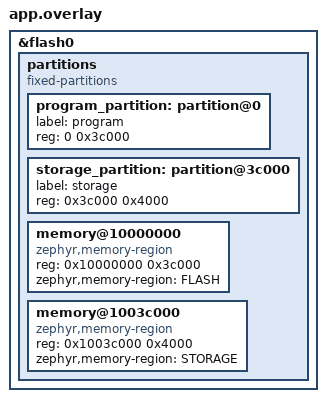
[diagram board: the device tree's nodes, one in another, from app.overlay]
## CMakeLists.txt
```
# Copyright (c) 2025 Analog Devices, Inc.
# SPDX-License-Identifier: Apache-2.0

cmake_minimum_required(VERSION 3.20.0)

find_package(Zephyr REQUIRED HINTS $ENV{ZEPHYR_BASE})

# Build app
project(motor_control)

target_sources(app PRIVATE
	src/main.c
	objdict/OD.c
	src/cia402.c
	src/tmc9660_params.c
)

zephyr_include_directories(objdict)
```

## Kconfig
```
# Copyright (c) 2025 Analog Devices, Inc.
# SPDX-License-Identifier: Apache-2.0

menu "Zephyr"
source "Kconfig.zephyr"
endmenu

menu "ADRD motor drive"

config SHELL_TMC_PARAMS
    bool "tmc_params shell command"
    depends on SHELL

config TMC_PARAMS_REFSW
    bool "Use parameters relating to reference switch"
    default n

config TMC_PARAMS_ABN1
    bool "Use parameters relating to ABN1 encoder"
    default y
    
config TMC_PARAMS_ABN2
    bool "Use parameters relating to ABN2 encoder"
    default n

config TMC_PARAMS_SPI
    bool "Use parameters relating to SPI encoder"
    default n
    
config TMC_PARAMS_HALL
    bool "Use parameters relating to Hall encoder"
    default y

config TMC_PARAMS_STEPDIR
    # ioan: would we *ever* need this on this board?
    bool "Use parameters relating to STEP/DIR input"
    default n

config TMC_RWE_PARAM_NAMES
    bool "Provide name strings for TMC9660 RWE parameters"
    depends on SHELL_TMC_PARAMS

config CIA402_THREAD_STACK_SIZE
    int "CiA 402 thread stack size"
    default 1024

endmenu
```

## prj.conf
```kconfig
# Copyright (c) 2024-2025 Analog Devices, Inc.
# SPDX-License-Identifier: Apache-2.0

CONFIG_CAN=y
CONFIG_CANOPEN=y
CONFIG_CANOPEN_LOG_LEVEL_INF=y
CONFIG_CANOPENNODE=y
CONFIG_CANOPENNODE_CONFIG_FILE="CO_config_custom.h"
CONFIG_CANOPENNODE_MAINLINE_THREAD_STACK_SIZE=1024
CONFIG_CANOPENNODE_SYNC_THREAD_STACK_SIZE=1024

CONFIG_CANOPENNODE_LEDS_USE_GPIO=n
CONFIG_CANOPENNODE_LEDS_USE_CALLBACK=y

CONFIG_LOG=y
CONFIG_REBOOT=y
CONFIG_LOG_SPEED=y

# CONFIG_CAN_LOG_LEVEL_DBG=y
# CONFIG_CANOPEN_LOG_LEVEL_DBG=y
CONFIG_CANOPEN_LOG_LEVEL_INF=y

CONFIG_SHELL=y
CONFIG_SHELL_MINIMAL=n
CONFIG_SHELL_TMC_PARAMS=y
CONFIG_TMC_RWE_PARAM_NAMES=n

CONFIG_FLASH=y
CONFIG_FLASH_MAP=y
CONFIG_SETTINGS=y
CONFIG_SETTINGS_RUNTIME=y
CONFIG_ZMS=y
CONFIG_SETTINGS_ZMS=y

CONFIG_COMMON_LIBC_MALLOC=y
CONFIG_BUILD_OUTPUT_META=y
```

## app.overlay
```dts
/*
 * Copyright (c) 2024-2025 Analog Devices, Inc.
 *
 * SPDX-License-Identifier: Apache-2.0
 */

&flash0 {
    partitions {
        compatible = "fixed-partitions";
        #address-cells = <0x1>;
        #size-cells = <0x1>;

        program_partition: partition@0 {
            label = "program";
            reg = <0 0x3c000>;
        };

        storage_partition: partition@3c000 {
            label = "storage";
            reg = <0x3c000 0x4000>;
        };

        /* Inform linker: */
        memory@10000000 {
            compatible = "zephyr,memory-region";
            reg = <0x10000000 0x3c000>;
            zephyr,memory-region = "FLASH";
        };

        memory@1003c000 {
            compatible = "zephyr,memory-region";
            reg = <0x1003c000 0x4000>;
            zephyr,memory-region = "STORAGE";
        };
    };
};
```

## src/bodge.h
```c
/*
 * Copyright (c) 2025 Analog Devices, Inc.
 *
 * SPDX-License-Identifier: Apache-2.0
 */

#ifndef BODGE_H_
#define BODGE_H_

#include <wrap_max32_sys.h>

static inline void calibrate_oscillator()
{
	MXC_SYS_ClockCalibrate(MXC_SYS_CLOCK_IPO);
}

#endif /* BODGE_H_ */
```

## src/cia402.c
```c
/*
 * Copyright (c) 2025 Analog Devices, Inc.
 *
 * SPDX-License-Identifier: Apache-2.0
 */

#include <zephyr/logging/log.h>
#include <stdlib.h>

#include "cia402.h"
#include "cia402_impl.h"

LOG_MODULE_REGISTER(cia402, LOG_LEVEL_INF);

enum cia402_statusword_bit {
    CIA402_SW_READYTOSWITCHON = 1 << 0,  // Ready to switch on
    CIA402_SW_SWITCHON = 1 << 1,         // Switched on (voltage applied to drive)
    CIA402_SW_OPERATIONEN = 1 << 2,      // Operation Enabled (+ quick stop / fault reaction)
    CIA402_SW_FAULT = 1 << 3,
    CIA402_SW_VOLTAGEEN = 1 << 4,        // Voltage is applied to drive
    CIA402_SW_QUICKSTOP = 1 << 5,        // 
    CIA402_SW_SWITCHONDISABLED = 1 << 6, //
    CIA402_SW_WARNING = 1 << 7,          // 
    CIA402_SW_MANUF1 = 1 << 8,           // Manufacturer-specific, unused
    CIA402_SW_REMOTE = 1 << 9,           // Set to 0 if PDOs are ignored (never??)
    CIA402_SW_TARGET = 1 << 10,          // Target reached
    CIA402_SW_LIMIT = 1 << 11,           // Internal limit active (e.g. software position limit)
    CIA402_SW_MOP1 = 1 << 12,            // Mode-of-operation specific:
    CIA402_SW_PP_ACK = CIA402_SW_MOP1,   // pp: Set-point acknowledge
    CIA402_SW_PV_SPEED = CIA402_SW_MOP1, // pv: Speed
    CIA402_SW_CS_FOL = CIA402_SW_MOP1,   // csp, csv, cst: Drive follows the command value
    CIA402_SW_MOP2 = 1 << 13,            // Mode-of-operation specific:
    CIA402_SW_PP_ERR = CIA402_SW_MOP2,   // pp: Following error
    CIA402_SW_PV_ERR = CIA402_SW_MOP2,   // pv: Max slippage error
    CIA402_SW_CS_ERR = CIA402_SW_MOP2,   // csp, csv, cst: Folowing error
    CIA402_SW_MANUF2 = 1 << 14,          // Manufacturer-specific, unused
    CIA402_SW_MANUF3 = 1 << 15,          // Manufacturer-specific, unused
};

enum cia402_controlword_bit {
    CIA402_CW_SWITCH_ON = 1 << 0,        // Switch on
    CIA402_CW_ENABLE_VOLTAGE = 1 << 1,   // Enable voltage
    CIA402_CW_QUICK_STOP = 1 << 2,       // Quick stop (0 = quick stop)
    CIA402_CW_ENABLE_OPERATION = 1 << 3, // Enable operation
    CIA402_CW_MOP1 = 1 << 4,             // Mode-of-operation specific:
    CIA402_CW_PP_NEWSP = CIA402_CW_MOP1, // pp: New set-point
    CIA402_CW_MOP2 = 1 << 5,             // Mode-of-operation specific:
    CIA402_CW_PP_IMM = CIA402_CW_MOP2,   // pp: Immediately assume set-point
    CIA402_CW_MOP3 = 1 << 6,             // Mode-of-operation specific:
    CIA402_CW_PP_REL = CIA402_CW_MOP3,   // pp: Set-point is relative
    CIA402_CW_FAULT_RESET = 1 << 7,      // Fault reset
    CIA402_CW_HALT = 1 << 8,             // Halt
};

struct cia402_priv {
    struct k_mutex lock; // ioan: What did I intend to symchronize with this lock...?

    // Profile position state
    bool pp_target_reached;
    int pp_target;
};

// CIA402_STATE_NOT_READY_TO_SWITCH_ON: low power, disabled drive, brake enabled if exists. run self-test + init
static inline void enter_not_ready_to_switch_on(struct cia402 *cia402) {
    LOG_INF("Entering state: NOT_READY_TO_SWITCH_ON");

    *cia402->statusword = 0;
    cia402_impl_statusword_tpdo(cia402);
}


// CIA402_STATE_SWITCH_ON_DISABLED: self-test + init ok. idle powered-down state
static inline void enter_switch_on_disabled(struct cia402 *cia402) {
    LOG_INF("Entering state: SWITCH_ON_DISABLED");

    cia402_impl_shutdown(cia402);

    int sw = *cia402->statusword;
    sw = (sw & ~0b1001111) | 0b1000000; // x1xx 0000
    sw &= ~CIA402_SW_VOLTAGEEN;
    // sw |= CIA402_SW_REMOTE; // ioan: is this the right place?
    *cia402->statusword = sw;
    cia402_impl_statusword_tpdo(cia402);
}


// CIA402_STATE_READY_TO_SWITCH_ON: maybe high power, drive disabled. intermediary state during motor power-up
static inline void enter_ready_to_switch_on(struct cia402 *cia402) {
    LOG_INF("Entering state: READY_TO_SWITCH_ON");
    
    int sw = *cia402->statusword;
    sw = (sw & ~0b1101111) | 0b0100001; // x01x 0001
    sw &= ~CIA402_SW_VOLTAGEEN;
    *cia402->statusword = sw;
    cia402_impl_statusword_tpdo(cia402);
}


// CIA402_STATE_SWITCHED_ON: high power, drive disabled. intermediary state during motor power-up
static inline void enter_switched_on(struct cia402 *cia402) {
    LOG_INF("Entering state: SWITCHED_ON");

    cia402_impl_start(cia402);
    
    int sw = *cia402->statusword;
    sw = (sw & ~0b1101111) | 0b0100011; // x01x 0011
    sw |= CIA402_SW_VOLTAGEEN;
    *cia402->statusword = sw;
    cia402_impl_statusword_tpdo(cia402);
}


// CIA402_STATE_OPERATION_ENABLED: high power, drive enabled, motor actively communicating and moving
static inline void enter_operation_enabled(struct cia402 *cia402) {
    LOG_INF("Entering state: OPERATION_ENABLED");
    
    int sw = *cia402->statusword;
    sw = (sw & ~0b1101111) | 0b0100111; // x01x 0111
    sw |= CIA402_SW_VOLTAGEEN;
    *cia402->statusword = sw;
    cia402_impl_statusword_tpdo(cia402);
}

static inline void run_mode_pp(struct cia402 *cia402) {
    uint16_t controlword = *cia402->controlword;
    uint16_t statusword = *cia402->statusword;

    // Parse controlword
    if(controlword & CIA402_CW_PP_NEWSP) {
        if((controlword & CIA402_CW_PP_IMM) || (cia402->priv->pp_target_reached || true)) { // target_reached doesn't work yet
            if(controlword & CIA402_CW_PP_REL) {
                // TODO: object 60F2 - relative to what
                cia402->priv->pp_target += *cia402->target_pos;
            } else {
                cia402->priv->pp_target = *cia402->target_pos;
            }

            statusword |= CIA402_SW_PP_ACK;
            *cia402->statusword = statusword;
            cia402_impl_statusword_tpdo(cia402);
        }
    } else {
        // Un-assert "ack" only after master un-asserts "new set-point"
        if(statusword & CIA402_SW_PP_ACK) {
            statusword &= ~CIA402_SW_PP_ACK;
            *cia402->statusword = statusword;
            cia402_impl_statusword_tpdo(cia402);
        }
    }

    bool halt = controlword & CIA402_CW_HALT;

    // Execute
    struct cia402_impl_pp_out out = cia402_impl_pp((struct cia402_impl_pp_in) {
        .halt = halt,
        .target_pos = cia402->priv->pp_target
    });

    // Set statusword
    statusword &= ~(CIA402_SW_PP_ERR | CIA402_SW_TARGET);
    if(out.pp_err) statusword |= CIA402_SW_PP_ERR;
    if(out.target_reached) statusword |= CIA402_SW_TARGET;
    *cia402->statusword = statusword;
}

static inline void run_mode_pv(struct cia402 *cia402) {
    uint16_t controlword = *cia402->controlword;
    uint16_t statusword = *cia402->statusword;

    // Parse controlword
    bool halt = controlword & CIA402_CW_HALT;

    // Execute
    struct cia402_impl_pv_out out = cia402_impl_pv((struct cia402_impl_pv_in) {
        .halt = halt,
        .target_vel = *cia402->target_vel
    });

    // Set statusword
    statusword &= ~(CIA402_SW_PV_SPEED | CIA402_SW_PV_ERR | CIA402_SW_TARGET);
    if(out.speed) statusword |= CIA402_SW_PV_SPEED;
    if(out.max_slip_err) statusword |= CIA402_SW_PV_ERR;    
    if(out.target_reached) statusword |= CIA402_SW_TARGET;
    *cia402->statusword = statusword;
}

static inline void run_mode_tq(struct cia402 *cia402) {
    uint16_t controlword = *cia402->controlword;
    uint16_t statusword = *cia402->statusword;

    // Parse controlword
    bool halt = controlword & CIA402_CW_HALT;

    // TODO: implement torque slope (object 6087)

    struct cia402_impl_tq_out out = cia402_impl_tq((struct cia402_impl_tq_in) {
        .halt = halt,
        .target_tor = *cia402->target_tor
    });

    statusword &= ~CIA402_SW_TARGET;
    if(out.target_reached) statusword |= CIA402_SW_TARGET;
    *cia402->statusword = statusword;
}

static inline void run_mode_csp(struct cia402 *cia402) {
    uint16_t statusword = *cia402->statusword;

    // Controlword: Cyclic synchronous modes have no mode-specific bits

    // Execute
    struct cia402_impl_csp_out out = cia402_impl_csp((struct cia402_impl_csp_in) {
        .target_pos = *cia402->target_pos
    });

    // Set statusword
    statusword &= ~(CIA402_SW_CS_ERR | CIA402_SW_CS_FOL);
    if(out.following_err) statusword |= CIA402_SW_CS_ERR;
    if(out.following) statusword |= CIA402_SW_CS_FOL;
    *cia402->statusword = statusword;
}

static inline void run_mode_csv(struct cia402 *cia402) {
    uint16_t statusword = *cia402->statusword;

    // Controlword: Cyclic synchronous modes have no mode-specific bits

    // Execute
    struct cia402_impl_csv_out out = cia402_impl_csv((struct cia402_impl_csv_in) {
        .target_vel = *cia402->target_vel
    });

    // Set statusword
    statusword &= ~(CIA402_SW_CS_ERR | CIA402_SW_CS_FOL);
    if(out.following) statusword |= CIA402_SW_CS_FOL;
    *cia402->statusword = statusword;
}

static inline void run_mode_cst(struct cia402 *cia402) {
    uint16_t statusword = *cia402->statusword;

    // Controlword: Cyclic synchronous modes have no mode-specific bits

    // Execute
    struct cia402_impl_cst_out out = cia402_impl_cst((struct cia402_impl_cst_in) {
        .target_tor = *cia402->target_tor
    });

    // Set statusword
    statusword &= ~(CIA402_SW_CS_ERR | CIA402_SW_CS_FOL);
    if(out.following) statusword |= CIA402_SW_CS_FOL;
    *cia402->statusword = statusword;
}

static inline void run_operation_enabled(struct cia402 *cia402) {
    const uint16_t initial_statusword = *cia402->statusword;
    enum cia402_mode_of_operation mode_req = *cia402->mop;
    enum cia402_mode_of_operation mode = *cia402->mop_display;

    // Handle mode change
    if(mode_req != mode) {
        LOG_INF("Setting mode of operation: %d %s", mode_req,
            mode_req == CIA402_MODE_PROFILE_POSITION ? "pp" :
            mode_req == CIA402_MODE_PROFILE_VELOCITY ? "pv" :
            mode_req == CIA402_MODE_PROFILE_TORQUE ? "tq" :
            mode_req == CIA402_MODE_CYCLIC_SYNCHRONOUS_POSITION ? "csp" :
            mode_req == CIA402_MODE_CYCLIC_SYNCHRONOUS_VELOCITY ? "csv" :
            mode_req == CIA402_MODE_CYCLIC_SYNCHRONOUS_TORQUE ? "cst" : "??");

        // Reset mode-specific bits
        cia402->priv->pp_target = *cia402->current_pos;
        cia402->priv->pp_target_reached = false;

        *cia402->mop_display = mode = mode_req;
        cia402_impl_mop_tpdo(cia402);
        cia402_impl_statusword_tpdo(cia402);
    }

    // Mode-specific logic
    switch(mode) {
        default: cia402_impl_halt(cia402); break; // Invalid mode
        case CIA402_MODE_PROFILE_POSITION:            run_mode_pp(cia402);  break;
        case CIA402_MODE_PROFILE_VELOCITY:            run_mode_pv(cia402);  break;
        case CIA402_MODE_PROFILE_TORQUE:              run_mode_tq(cia402);  break;
        case CIA402_MODE_CYCLIC_SYNCHRONOUS_POSITION: run_mode_csp(cia402); break;
        case CIA402_MODE_CYCLIC_SYNCHRONOUS_VELOCITY: run_mode_csv(cia402); break;
        case CIA402_MODE_CYCLIC_SYNCHRONOUS_TORQUE:   run_mode_cst(cia402); break;
    }

    if(*cia402->statusword != initial_statusword) {
        cia402_impl_statusword_tpdo(cia402);
    }
}


// CIA402_STATE_QUICK_STOP_ACTIVE: stop motor, then go to SWITCH_ON_DISABLED
static inline void enter_quick_stop_active(struct cia402 *cia402) {
    LOG_INF("Entering state: QUICK_STOP_ACTIVE");

    cia402_impl_stop(cia402);
    
    int sw = *cia402->statusword;
    sw = (sw & ~0b1101111) | 0b0000111; // x00x 0111
    *cia402->statusword = sw;
    cia402_impl_statusword_tpdo(cia402);
}


// CIA402_STATE_FAULT_REACTION_ACTIVE: stop motor, then go to FAULT
static inline void enter_fault_reaction_active(struct cia402 *cia402) {
    LOG_INF("Entering state: FAULT_REACTION_ACTIVE");

    cia402_impl_stop(cia402);
    
    int sw = *cia402->statusword;
    sw = (sw & ~0b1001111) | 0b0001111; // x0xx 1111
    *cia402->statusword = sw;
    cia402_impl_statusword_tpdo(cia402);
}

// CIA402_STATE_FAULT: stay in this state until explicitly taken out
static inline void enter_fault(struct cia402 *cia402) {
    LOG_INF("Entering state: FAULT");
    
    cia402_impl_shutdown(cia402);

    int sw = *cia402->statusword;
    sw = (sw & ~0b1001111) | 0b0001000; // x0xx 1000
    sw &= ~CIA402_SW_VOLTAGEEN;
    *cia402->statusword = sw;
    cia402_impl_statusword_tpdo(cia402);
}

void cia402_tick(struct cia402 *cia402, bool quick) {
    k_mutex_lock(&cia402->priv->lock, K_FOREVER);

    const enum cia402_state state = cia402->state;
    enum cia402_state nextState = state;
    uint16_t controlword = *cia402->controlword;

    if(state == CIA402_STATE_OPERATION_ENABLED) {
        run_operation_enabled(cia402);
    }

    // Parse ControlWord bits (cia402 v2.0 10.3.1)
    const bool cw_fault_reset      = controlword & CIA402_CW_FAULT_RESET;
    const bool cw_enable_operation = controlword & CIA402_CW_ENABLE_OPERATION;
    const bool cw_quick_stop       = controlword & CIA402_CW_QUICK_STOP;
    const bool cw_enable_voltage   = controlword & CIA402_CW_ENABLE_VOLTAGE;
    const bool cw_switch_on        = controlword & CIA402_CW_SWITCH_ON;

    // Compute commands (cia402 v2.0 10.3.1 table 4)
    const bool com_fault_reset       = cw_fault_reset;
    const bool com_shutdown          = !cw_fault_reset && cw_quick_stop && cw_enable_voltage && !cw_switch_on;
    const bool com_switch_on         = !cw_fault_reset && cw_quick_stop && cw_enable_voltage && cw_switch_on; // Enable operaion is "=0 OR =1" so an effective X
    const bool com_enable_operation  = !cw_fault_reset && cw_enable_operation && cw_quick_stop && cw_enable_voltage && cw_switch_on;
    const bool com_disable_operation = !cw_fault_reset && !cw_enable_operation && cw_quick_stop && cw_enable_voltage && cw_switch_on;
    const bool com_disable_voltage   = !cw_fault_reset && !cw_enable_voltage;
    const bool com_quick_stop        = !cw_fault_reset && !cw_quick_stop && cw_enable_voltage;

    // Compute transitions (via402 v2.0 10.1.1.2)
    // Transition 1: Initialization
    if(state == CIA402_STATE_NOT_READY_TO_SWITCH_ON) {
        if(cia402_impl_initialize(cia402)) {
            nextState = CIA402_STATE_SWITCH_ON_DISABLED;
        } else {
            LOG_ERR("COULD NOT INITIALIZE DRIVE");
            k_oops();
            return;
        }
    }

    // Transitions 2, 3, 4: SWITCH_ON_DISABLED -> READY_TO_SWITCH_ON -> SWITCHED_ON -> OPERATION_ENABLE
    if(state == CIA402_STATE_SWITCH_ON_DISABLED && com_shutdown)                                           nextState = CIA402_STATE_READY_TO_SWITCH_ON;
    if(state == CIA402_STATE_READY_TO_SWITCH_ON && com_switch_on)                                          nextState = CIA402_STATE_SWITCHED_ON;
    if(state == CIA402_STATE_SWITCHED_ON        && com_enable_operation && cia402_impl_is_started(cia402)) nextState = CIA402_STATE_OPERATION_ENABLED;

    // Transitions 5, 6, 7: OPERATION_ENABLE -> SWITCHED_ON -> READY_TO_SWITCH_ON -> SWITCH_ON_DISABLED
    if(state == CIA402_STATE_OPERATION_ENABLED  && com_disable_operation)                   nextState = CIA402_STATE_SWITCHED_ON;
    if(state == CIA402_STATE_SWITCHED_ON        && com_shutdown)                            nextState = CIA402_STATE_READY_TO_SWITCH_ON;
    if(state == CIA402_STATE_READY_TO_SWITCH_ON && (com_quick_stop || com_disable_voltage)) nextState = CIA402_STATE_SWITCH_ON_DISABLED;

    // Transitions 8, 9: Power off from OPERATION_ENABLED
    if(state == CIA402_STATE_OPERATION_ENABLED && com_shutdown)        nextState = CIA402_STATE_READY_TO_SWITCH_ON;
    if(state == CIA402_STATE_OPERATION_ENABLED && com_disable_voltage) nextState = CIA402_STATE_SWITCH_ON_DISABLED;

    // Transitions 10, 11, 12: Quick stop
    if(state == CIA402_STATE_SWITCHED_ON && (com_quick_stop || com_disable_voltage)) nextState = CIA402_STATE_SWITCH_ON_DISABLED;
    if(state == CIA402_STATE_OPERATION_ENABLED && com_quick_stop)                    nextState = CIA402_STATE_QUICK_STOP_ACTIVE;
    if(state == CIA402_STATE_QUICK_STOP_ACTIVE && com_disable_voltage)               nextState = CIA402_STATE_SWITCH_ON_DISABLED;
    if(state == CIA402_STATE_QUICK_STOP_ACTIVE && cia402_impl_is_stopped(cia402))    nextState = CIA402_STATE_SWITCH_ON_DISABLED;

    // Transition 13 triggered by cia402_enter_fault
    // Transition 14, 15: FAULT_REACTION_ACTIVE -> FAULT -> SWITCH_ON_DISABLED
    if(state == CIA402_STATE_FAULT_REACTION_ACTIVE && cia402_impl_is_stopped(cia402)) nextState = CIA402_STATE_FAULT;
    if(state == CIA402_STATE_FAULT && com_fault_reset)                                nextState = CIA402_STATE_SWITCH_ON_DISABLED;

    if(nextState != state) {
        switch(cia402->state = nextState) {
            case CIA402_STATE_NOT_READY_TO_SWITCH_ON: enter_not_ready_to_switch_on(cia402); break;
            case CIA402_STATE_SWITCH_ON_DISABLED:     enter_switch_on_disabled(cia402); break;
            case CIA402_STATE_READY_TO_SWITCH_ON:     enter_ready_to_switch_on(cia402); break;
            case CIA402_STATE_SWITCHED_ON:            enter_switched_on(cia402); break;
            case CIA402_STATE_OPERATION_ENABLED:      enter_operation_enabled(cia402); break;
            case CIA402_STATE_QUICK_STOP_ACTIVE:      enter_quick_stop_active(cia402); break;
            case CIA402_STATE_FAULT_REACTION_ACTIVE:  enter_fault_reaction_active(cia402); break;
            case CIA402_STATE_FAULT:                  enter_fault(cia402); break;
        }
    }

    //cia402_impl_statusword_tpdo(cia402);

    k_mutex_unlock(&cia402->priv->lock);
}

void cia402_enter_fault(struct cia402 *cia402) {
    k_mutex_lock(&cia402->priv->lock, K_FOREVER);
    if(cia402->state != CIA402_STATE_FAULT && cia402->state != CIA402_STATE_FAULT_REACTION_ACTIVE) {
	    cia402->state = CIA402_STATE_FAULT_REACTION_ACTIVE;
	    enter_fault_reaction_active(cia402);
    }
    k_mutex_unlock(&cia402->priv->lock);
}

void cia402_init(struct cia402* cia402) {
    cia402->priv = malloc(sizeof(struct cia402_priv));
    memset(cia402->priv, 0, sizeof(*cia402->priv));

    k_mutex_init(&cia402->priv->lock);
    k_mutex_lock(&cia402->priv->lock, K_FOREVER);

    cia402->state = CIA402_STATE_NOT_READY_TO_SWITCH_ON;
    enter_not_ready_to_switch_on(cia402);

    k_mutex_unlock(&cia402->priv->lock);
}
```

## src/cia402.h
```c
/*
 * Copyright (c) 2025 Analog Devices, Inc.
 *
 * SPDX-License-Identifier: Apache-2.0
 */

#ifndef CIA402_H_
#define CIA402_H_

#include <zephyr/kernel.h>

enum cia402_state {
    CIA402_STATE_NOT_READY_TO_SWITCH_ON, // Low power, disabled drive, brake enabled if exists. Run self-test + init
    CIA402_STATE_SWITCH_ON_DISABLED,     // Idle powered-down state
    CIA402_STATE_READY_TO_SWITCH_ON,     // Intermediary state during motor power-up. Maybe high power (depends on application), drive disabled
    CIA402_STATE_SWITCHED_ON,            // Intermediary state during motor power-up. High power, drive disabled
    CIA402_STATE_OPERATION_ENABLED,      // Motor powered on, drive enabled
    CIA402_STATE_QUICK_STOP_ACTIVE,      // Quick stop active
    CIA402_STATE_FAULT_REACTION_ACTIVE,  // Stopping because of a fault condition
    CIA402_STATE_FAULT                   // Final fault state. Needs explicit action to return to the rest of the state machine
};

enum cia402_mode_of_operation {
    CIA402_MODE_INACTIVE = 0,
    CIA402_MODE_PROFILE_POSITION = 1,
    CIA402_MODE_PROFILE_VELOCITY = 3,
    CIA402_MODE_PROFILE_TORQUE = 4,
    CIA402_MODE_CYCLIC_SYNCHRONOUS_POSITION = 8,
    CIA402_MODE_CYCLIC_SYNCHRONOUS_VELOCITY = 9,
    CIA402_MODE_CYCLIC_SYNCHRONOUS_TORQUE = 10,
};

struct cia402_priv;

struct cia402 {
    struct cia402_priv *priv;

    enum cia402_state state;

    // Pointers to OD storage
    uint16_t *controlword; // 6040 ControlWord
    uint16_t *statusword;  // 6041 StatusWord
    uint8_t  *mop;         // 6060 ModesOfOperation
    uint8_t  *mop_display; // 6061 ModesOfOperationDisplay
    int32_t  *target_pos;  // 607A TargetPosition
    int32_t  *target_vel;  // 60FF TargetVelocity
    int16_t  *target_tor;  // 6071 TargetTorque
    int32_t  *current_pos; // 6063 PositionActualValue
};

// Initialize CiA 402 state machine 
void cia402_init(struct cia402* cia402);

// Enter fault and trigger application specific motor stop logic
void cia402_enter_fault(struct cia402 *cia402);

// Step CiA 402 state machine once
void cia402_tick(struct cia402 *cia402, bool quick);

#endif /* CIA402_H_ */
```

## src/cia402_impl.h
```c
/*
 * Copyright (c) 2025 Analog Devices, Inc.
 *
 * SPDX-License-Identifier: Apache-2.0
 */

 #ifndef CIA402_IMPL_H_
#define CIA402_IMPL_H_

#include <stdbool.h>

/**
 * @defgroup cia402_impl CiA 402 application-specific implementation
 * @{
 */

/** @brief Trigger TPDO of StatusWord */
extern void cia402_impl_statusword_tpdo();

/** @brief Trigger TPDO of ModeOfOperationDisplay */
extern void cia402_impl_mop_tpdo();

/** @brief Initialize drive */
extern bool cia402_impl_initialize();

/** @brief Power off motor */
extern void cia402_impl_shutdown();

/** @brief Power on motor, starting with initialization */
extern void cia402_impl_start();

/** @brief Check if initialization was finished and motor may be controller. Called after `cia402_impl_start`. */
extern bool cia402_impl_is_started();

/** @brief Halt motor without powering it off. Returns true if the motor has stopped. */
extern bool cia402_impl_halt();

/** @brief Initiate fault / quick stop but keep drive powered on (as opposed to `cia402_impl_shutdown`) */
extern void cia402_impl_stop();

/** @brief Check if stop action was finished. Called after `cia402_impl_stop`. */
extern bool cia402_impl_is_stopped();

/**
 * @defgroup cia402_impl_pp Profile Position mode
 * @{
 */

/** @brief Data passed to profile position implementation */
struct cia402_impl_pp_in {
    int target_pos;
    bool halt;
};

/** @brief Data returned from profile position implementation */
struct cia402_impl_pp_out {
    bool target_reached;
    bool pp_err;
};

/** @brief Implementation of profile position mode of operation */
extern struct cia402_impl_pp_out cia402_impl_pp(struct cia402_impl_pp_in);

/** @} */ // cia402_impl_pp

/**
 * @defgroup cia402_impl_pv Profile Velocity mode
 * @{
 */

/** @brief Data passed to profile velocity implementation */
struct cia402_impl_pv_in {
    int target_vel;
    bool halt;
};

/** @brief Data returned from profile velocity implementation */
struct cia402_impl_pv_out {
    bool target_reached;
    bool speed;
    bool max_slip_err;
};

/** @brief Implementation of profile velocity mode of operation */
extern struct cia402_impl_pv_out cia402_impl_pv(struct cia402_impl_pv_in);

/** @} */ // cia402_impl_pv

/**
 * @defgroup cia402_impl_tq Profile Torque mode
 * @{
 */

/** @brief Data passed to profile velocity implementation */
struct cia402_impl_tq_in {
    int target_tor;
    bool halt;
};

/** @brief Data returned from profile velocity implementation */
struct cia402_impl_tq_out {
    bool target_reached;
};

/** @brief Implementation of profile toruqe mode of operation */
extern struct cia402_impl_tq_out cia402_impl_tq(struct cia402_impl_tq_in);

/** @} */ // cia402_impl_tq

/**
 * @defgroup cia402_impl_csp Cyclic Synchronous Position mode
 * @{
 */

/** @brief Data passed to cyclic synchronous position implementation */
struct cia402_impl_csp_in {
    int target_pos;
};

/** @brief Data returned from profile velocity implementation */
struct cia402_impl_csp_out {
    bool following;
    bool following_err;
};

/** @brief Implementation of cyclic synchronous position mode of operation */
extern struct cia402_impl_csp_out cia402_impl_csp(struct cia402_impl_csp_in);

/** @} */ // cia402_impl_csp

/**
 * @defgroup cia402_impl_csv Cyclic Synchronous Velocity mode
 * @{
 */

/** @brief Data passed to cyclic synchronous velocity implementation */
struct cia402_impl_csv_in {
    int target_vel;
};

/** @brief Data returned from profile velocity implementation */
struct cia402_impl_csv_out {
    bool following;
};

/** @brief Implementation of cyclic synchronous velocity mode of operation */
extern struct cia402_impl_csv_out cia402_impl_csv(struct cia402_impl_csv_in);

/** @} */ // cia402_impl_csv

/**
 * @defgroup cia402_impl_cst Cyclic Synchronous Torque mode
 * @{
 */

/** @brief Data passed to cyclic synchronous torque implementation */
struct cia402_impl_cst_in {
    int target_tor;
};

/** @brief Data returned from profile velocity implementation */
struct cia402_impl_cst_out {
    bool following;
};

/** @brief Implementation of cyclic synchronous torque mode of operation */
extern struct cia402_impl_cst_out cia402_impl_cst(struct cia402_impl_cst_in);

/** @} */ // cia402_impl_cst

/** @} */ // cia402_impl

#endif /* CIA402_IMPL_H_ */
```

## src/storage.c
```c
/*
 * Copyright (c) 2025 Analog Devices, Inc.
 *
 * SPDX-License-Identifier: Apache-2.0
 */

#include "storage.h"
#include <zephyr/storage/flash_map.h>
#include <zephyr/fs/nvs.h>
#include <zephyr/logging/log.h>

LOG_MODULE_REGISTER(storage, LOG_LEVEL_INF);

#define NVS_PARTITION        storage_partition
#define NVS_PARTITION_DEVICE FIXED_PARTITION_DEVICE(NVS_PARTITION)
#define NVS_PARTITION_OFFSET FIXED_PARTITION_OFFSET(NVS_PARTITION)

struct nvs_fs fs = {
    .flash_device = NVS_PARTITION_DEVICE,
    .offset = NVS_PARTITION_OFFSET,
    .sector_size = 8192, // Page size = 8192
    .sector_count = 2, // Fill a page
};

void storage_init() {
    int ret = nvs_mount(&fs);

    if(ret) {
        LOG_ERR("Could not mount NVS");
    }

    LOG_INF("NVS free space: %d", nvs_calc_free_space(&fs));
}

int storage_get(enum nvs_id id, void *data, size_t len) {
    int ret = nvs_read(&fs, id, data, len);
    if(ret < 0) return ret;
    return 0;
}

int storage_put(enum nvs_id id, void *data, size_t len) {
    int ret = nvs_write(&fs, id, data, len);
    if(ret < 0) return ret;
    return 0;
}
```

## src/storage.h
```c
/*
 * Copyright (c) 2025 Analog Devices, Inc.
 *
 * SPDX-License-Identifier: Apache-2.0
 */

#ifndef __STORAGE_H
#define __STORAGE_H

#include <sys/types.h>

enum nvs_id {
    TMC9660_PARAMS_STORAGE = 0,
};

void storage_init();
int storage_get(enum nvs_id id, void *data, size_t len);
int storage_put(enum nvs_id id, void *data, size_t len);

#endif /* __STORAGE_H */
```

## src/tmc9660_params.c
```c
/*
 * Copyright (c) 2025 Analog Devices, Inc.
 *
 * SPDX-License-Identifier: Apache-2.0
 */

#define OD_DEFINITION
#include <301/CO_ODinterface.h>
#undef OD_DEFINITION

#include <zephyr/sys/__assert.h>
#include <zephyr/logging/log.h>
#include <stdlib.h>

#ifdef CONFIG_SHELL_TMC_PARAMS
#include <zephyr/shell/shell.h>
#endif /* CONFIG_SHELL_TMC_PARAMS */

#include <app/drivers/misc/tmc9660/tmc9660.h>

#include "OD.h"
#include "tmc9660_params.h"

LOG_MODULE_REGISTER(tmc9660_params, LOG_LEVEL_DBG);

extern struct device *g_tmc9660;

ODR_t tmc_extension_write(OD_stream_t *stream, const void *buf, OD_size_t count, OD_size_t *countWritten) {
	__ASSERT(count == 4, "TMC param OD write invalid. Expected size 4, got %d", count);

	int tmc_param_id = stream->index - 0x2000;
	int ret = tmc9660_set_param_retry(g_tmc9660, tmc_param_id, *(int32_t *)buf, 3);
	LOG_DBG("OD write TMC param %d value %d returned %d", tmc_param_id, *(int32_t *)buf, ret);
	*countWritten = 4;

    // Mirror value in RAM as well
    int actual_val = *(int32_t *)buf;
    if(ret != 0) {
        // Write failed, get actual valud
        tmc9660_get_param(g_tmc9660, tmc_param_id, &actual_val);
    }
    *(int32_t *)stream->dataOrig = actual_val;

	if(ret == 0) return ODR_OK;
	if(ret == -EINVAL) return ODR_INVALID_VALUE;
	if(ret == -EIO) return ODR_HW;
	if(ret == -EAGAIN) return ODR_HW; // If 3 retries isn't enough, report hardware error
	return ODR_UNSUPP_ACCESS; // Catch-all for other errors
}

ODR_t tmc_extension_read(OD_stream_t *stream, void *buf, OD_size_t count, OD_size_t *countRead) {
	__ASSERT(count == 4, "TMC param OD read invalid. Expected size 4, got %d", count);

	int tmc_param_id = stream->index - 0x2000;
	int ret = tmc9660_get_param_retry(g_tmc9660, tmc_param_id, buf, 3);
	LOG_DBG("OD read TMC param %d value %d returned %d", tmc_param_id, *(int32_t *)buf, ret);
	*countRead = 4;

    // Mirror value in RAM as well
    int actual_val = *(int32_t *)buf;
    *(int32_t *)stream->dataOrig = actual_val;
	
	if(ret == 0) return ODR_OK;
	if(ret == -EINVAL) return ODR_INVALID_VALUE;
	if(ret == -EIO) return ODR_HW;
	if(ret == -EAGAIN) return ODR_HW; // If 3 retries isn't enough, report hardware error
	return ODR_UNSUPP_ACCESS; // Catch-all for other errors
}

OD_extension_t tmc_params_extensions[OD_CNT_TMC_PARAMS] = { 0 };

void tmc_params_init(void) {
	/* 
	 * Iterate through all CANopen OD entries, mapping 0x2000 - 0x2200 to TMC parameters 0x000 - 0x200.
	 * Set OD extensions with proper read/write handlers based on whether OD entry allows read/write.
     * Set values based on what is in RAM (for startup). Should be run after canopen storage initialization populates OD_PERSIST_TMC with data from flash. 
	 */

	memset(tmc_params_extensions, 0, sizeof(tmc_params_extensions));

	int ok = 0;
	int ext_idx = 0;
	for(int i = 0; i < OD->size; i++) {
		OD_entry_t *entry = &OD->list[i];
		const OD_obj_var_t *var = (const OD_obj_var_t *) entry->odObject;
		OD_extension_t *extension = &tmc_params_extensions[ext_idx];

		if(entry->index < 0x2000 || entry->index > 0x2200) continue;

		// Check if dataOrig (i.e. the place in RAM where the parameter value is actually stored)
		// is inside OD_PERSIST_TMC. That means it's a parameter we persist, so which we want to
		// synchronize between RAM and the TMC9660.
		if(var->dataOrig >= (void*)&OD_PERSIST_TMC && var->dataOrig < (void*)(&OD_PERSIST_TMC+1)) {
			ok |= tmc9660_set_param_retry(g_tmc9660, entry->index - 0x2000, *(int*)var->dataOrig, 3);
		}

		if((var->attribute & ODA_SDO_R) == ODA_SDO_R) {
			extension->read = tmc_extension_read;
		}

		if((var->attribute & ODA_SDO_W) == ODA_SDO_W) {
			extension->write = tmc_extension_write;
		}

		OD_extension_init(entry, extension);
		ext_idx++;
	}

	if(ok) {
		LOG_WRN("Not all TMC9660 parameters could be written!");
	}
}

#ifdef CONFIG_SHELL_TMC_PARAMS

int cmd_tmc_sap(struct shell *sh, int argc, char **argv) {
    int param_id = atoi(argv[1]);
    int param_val = atoi(argv[2]);
    return tmc9660_set_param(g_tmc9660, param_id, param_val);
}

int cmd_tmc_gap(struct shell *sh, int argc, char **argv) {
    int param_id = atoi(argv[1]);
    int val = 0;
    int ret = tmc9660_get_param(g_tmc9660, param_id, &val);
    if(ret == 0)
        shell_print(sh, "%d", val);
    else
        shell_error(sh, "Error %d", ret);
    return ret;
}

int cmd_tmc_rwe_show(struct shell *sh, int argc, char **argv) {
	/* FIXME
	int ret = 0;

	ret = storage_get(TMC9660_PARAMS_STORAGE, tmc9660_rwe_param_rambuf, sizeof(tmc9660_rwe_param_rambuf));
	if(ret) {
		LOG_ERR("Could not get TMC9660 RWE params from flash: %d", ret);
	}

    #ifdef CONFIG_TMC_RWE_PARAM_NAMES
    char *name_ptr = tmc9660_rwe_param_names;
    #endif
    for(int i = 0; i < tmc9660_rwe_param_count; i++) {
        int param_id = tmc9660_rwe_param_ids[i];
        int flash_value = tmc9660_rwe_param_rambuf[i];
        int tmc_value = 0xcafebabe;
        int ret = tmc9660_get_param(g_tmc9660, param_id, &tmc_value);

        if(ret) {
#ifdef CONFIG_TMC_RWE_PARAM_NAMES
            shell_warn(sh, "Error %d reading %s", ret, name_ptr);
#else
            shell_warn(sh, "Error %d reading %d", ret, param_id);
#endif
        }

        if(flash_value == tmc_value) {
#ifdef CONFIG_TMC_RWE_PARAM_NAMES
            shell_print(sh, "%s = %d", name_ptr, tmc_value);
#else
            shell_print(sh, "%d = %d", param_id, tmc_value);
#endif
        } else {
#ifdef CONFIG_TMC_RWE_PARAM_NAMES
            shell_warn(sh, "%s = %d (saved: %d)", name_ptr, tmc_value, flash_value);
#else
            shell_warn(sh, "%d = %d (saved: %d)", param_id, tmc_value, flash_value);
#endif
        }

#ifdef CONFIG_TMC_RWE_PARAM_NAMES
        while(*name_ptr++); // Advance to next string
#endif
    }

    return 0; */

	return -1;
}

int cmd_tmc_rwe_load(struct shell *sh, int argc, char **argv) {
	/* FIXME
    tmc_params_load(g_tmc9660);
    cmd_tmc_rwe_show(sh, argc, argv);
    return 0;
    */
	return -1;
}

int cmd_tmc_rwe_save(struct shell *sh, int argc, char **argv) {
	/* FIXME
    tmc_params_save(g_tmc9660);
    cmd_tmc_rwe_show(sh, argc, argv);
    return 0;
    */
	return -1;
}

int cmd_tmc_flags(struct shell *sh, int argc, char **argv) {
	int flags = 0;
	tmc9660_get_param(g_tmc9660, GENERAL_STATUS_FLAGS, &flags);

	if(flags & 1) shell_print(sh, "REGULATION_STOPPED");
	if(flags & 2) shell_print(sh, "REGULATION_TORQUE");
	if(flags & 4) shell_print(sh, "REGULATION_VELOCITY");
	if(flags & 8) shell_print(sh, "REGULATION_POSITION");
	if(flags & 16) shell_print(sh, "CONFIG_STORED");
	if(flags & 32) shell_print(sh, "CONFIG_LOADED");
	if(flags & 64) shell_print(sh, "CONFIG_READ_ONLY");
	if(flags & 128) shell_print(sh, "TMCL_SCRIPT_READ_ONLY");
	if(flags & 256) shell_print(sh, "BRAKE_CHOPPER_ACTIVE");
	if(flags & 512) shell_print(sh, "POSITION_REACHED");
	if(flags & 1024) shell_print(sh, "VELOCITY_REACHED");
	if(flags & 2048) shell_print(sh, "ADC_OFFSET_CALIBRATED");
	if(flags & 4096) shell_print(sh, "RAMPER_LATCHED");
	if(flags & 8192) shell_print(sh, "RAMPER_EVENT_STOP_SWITCH");
	if(flags & 16384) shell_print(sh, "RAMPER_EVENT_STOP_DEVIATION");
	if(flags & 32768) shell_print(sh, "RAMPER_VELOCITY_REACHED");
	if(flags & 65536) shell_print(sh, "RAMPER_POSITION_REACHED");
	if(flags & 131072) shell_print(sh, "RAMPER_SECOND_MOVE");
	if(flags & 262144) shell_print(sh, "IIT_1_ACTIVE");
	if(flags & 524288) shell_print(sh, "IIT_2_ACTIVE");
	if(flags & 1048576) shell_print(sh, "REFSEARCH_FINISHED");
	if(flags & 2097152) shell_print(sh, "Y2_USED_FOR_BRAKING");
	if(flags & 4194304) shell_print(sh, "FLASH_STIMULUS_AVAILABLE");
	if(flags & 8388608) shell_print(sh, "STEPDIR_INPUT_AVAILABLE");
	if(flags & 16777216) shell_print(sh, "RIGHT_REF_SWITCH_AVAILABLE");
	if(flags & 33554432) shell_print(sh, "HOME_REF_SWITCH_AVAILABLE");
	if(flags & 67108864) shell_print(sh, "LEFT_REF_SWITCH_AVAILABLE");
	if(flags & 134217728) shell_print(sh, "ABN2_FEEDBACK_AVAILABLE");
	if(flags & 268435456) shell_print(sh, "HALL_FEEDBACK_AVAILABLE");
	if(flags & 536870912) shell_print(sh, "ABN1_FEEDBACK_AVAILABLE");
	if(flags & 1073741824) shell_print(sh, "SPI_FLASH_AVAILABLE");
	if(flags & 2147483648) shell_print(sh, "I2C_EEPROM_AVAILABLE");

	return 0;
}

int cmd_tmc_boot(struct shell *sh, int argc, char **argv) {
	int ret = tmc9660_set_param_retry(g_tmc9660, COMMUTATION_MODE, 0, 3); // Stop commutation, see errata 3
	if(ret < 0) {
		shell_print(sh, "Could not stop commutation. NOT entering bootloader!");
		return ret;
	}

	ret = tmc9660_tmcl_command(g_tmc9660, 242, 0x81, 0x92, 0xa3b4c5d6, NULL);
	if(ret != -5) {
		shell_print(sh, "Expected status -5, got %d", ret);
		return -1;
	}

	shell_print(sh, "Entered bootloader! Motor control will not work, expect application errors");
	return 0;
}

SHELL_STATIC_SUBCMD_SET_CREATE(sub_tmc,
    SHELL_CMD_ARG(gap, NULL, "Get parameter", cmd_tmc_gap, 2, 0),
    SHELL_CMD_ARG(sap, NULL, "Set parameter", cmd_tmc_sap, 3, 0),
    SHELL_CMD(flags, NULL, "Show current flags", cmd_tmc_flags),
    // SHELL_CMD_ARG(rwe_show, NULL, "Show RWE parameters", cmd_tmc_rwe_show, 0, 1),
    // SHELL_CMD(rwe_save, NULL, "Save all current parameters to flash (run this after tuning)", cmd_tmc_rwe_save),
    // SHELL_CMD(rwe_load, NULL, "Load all RWE parameters from flash", cmd_tmc_rwe_load),
    SHELL_CMD(boot, NULL, "Exit parameter mode to bootloader", cmd_tmc_boot),
    SHELL_SUBCMD_SET_END
);
SHELL_CMD_REGISTER(tmc, &sub_tmc, "TMC9660 commands", NULL);

#endif /* CONFIG_SHELL_TMC_PARAMS */
```

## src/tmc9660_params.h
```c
/*
 * Copyright (c) 2025 Analog Devices, Inc.
 *
 * SPDX-License-Identifier: Apache-2.0
 */

#ifndef TMC_PARAMS_H_
#define TMC_PARAMS_H_

/**
 * @brief Initialize TMC parameter storage, bind to CANopen OD
 */
void tmc_params_init(void);

#endif /* TMC_PARAMS_H_ */
```
